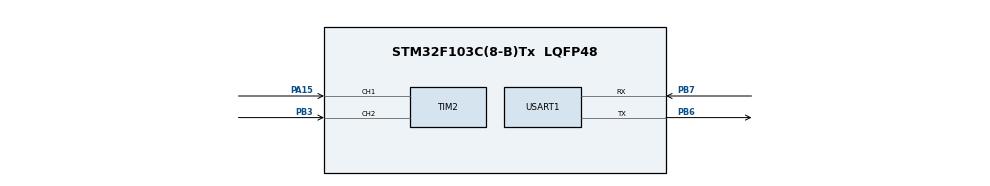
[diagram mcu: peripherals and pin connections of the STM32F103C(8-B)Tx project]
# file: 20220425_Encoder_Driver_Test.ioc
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Mcu.Family=STM32F1
Mcu.Name=STM32F103C(8-B)Tx
Mcu.Package=LQFP48
NVIC.PriorityGroup=NVIC_PRIORITYGROUP_4
NVIC.TIM4_IRQn=true\:0\:0\:false\:false\:true\:true\:true
PA13.Mode=Serial_Wire
PA13.Signal=SYS_JTMS-SWDIO
PA14.Mode=Serial_Wire
PA14.Signal=SYS_JTCK-SWCLK
PA15.GPIO_PuPd=GPIO_PULLUP
PA15.Signal=S_TIM2_CH1_ETR
PB3.GPIO_PuPd=GPIO_PULLUP
PB3.Signal=S_TIM2_CH2
PB6.Mode=Asynchronous
PB6.Signal=USART1_TX
PB7.Mode=Asynchronous
PB7.Signal=USART1_RX
ProjectManager.HeapSize=0x200
ProjectManager.StackSize=0x400
ProjectManager.TargetToolchain=STM32CubeIDE
RCC.APB1Freq_Value=8000000
RCC.APB2Freq_Value=8000000
SH.S_TIM2_CH1_ETR.0=TIM2_CH1,Encoder_Interface
SH.S_TIM2_CH2.0=TIM2_CH2,Encoder_Interface
TIM2.EncoderMode=TIM_ENCODERMODE_TI12
TIM2.IC1Filter=15
TIM2.IC2Filter=15
TIM4.AutoReloadPreload=TIM_AUTORELOAD_PRELOAD_ENABLE
TIM4.Period=200
TIM4.Prescaler=8000
USART1.VirtualMode=VM_ASYNC
VP_TIM4_VS_ClockSourceINT.Mode=Internal
board=custom

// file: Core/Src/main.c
/* USER CODE BEGIN Header */
/**
  ******************************************************************************
  * @file           : main.c
  * @brief          : Main program body
  ******************************************************************************
  * @attention
  *
  * Copyright (c) 2022 STMicroelectronics.
  * All rights reserved.
  *
  * This software is licensed under terms that can be found in the LICENSE file
  * in the root directory of this software component.
  * If no LICENSE file comes with this software, it is provided AS-IS.
  *
  ******************************************************************************
  */
/* USER CODE END Header */
#include "main.h"
#include "tim.h"
#include "usart.h"
#include "gpio.h"

/* USER CODE BEGIN Includes */
#include "rotary.h"
/* USER CODE END Includes */

/* USER CODE BEGIN PV */
uint8_t	MSG[50] = {'/0'};
/* USER CODE END PV */

void SystemClock_Config(void);

int main(void)
{

  /* MCU Configuration--------------------------------------------------------*/

  /* Reset of all peripherals, Initializes the Flash interface and the Systick. */
  HAL_Init();

  /* Configure the system clock */
  SystemClock_Config();

  /* Initialize all configured peripherals */
  MX_GPIO_Init();
  MX_USART1_UART_Init();
  MX_TIM2_Init();
  MX_TIM4_Init();
  /* USER CODE BEGIN 2 */
  HAL_ROTARY_Start(&htim2, &htim4, 8000);
  /* USER CODE END 2 */

  /* Infinite loop */
  while (1)
  {

    /* USER CODE BEGIN 3 */
	  sprintf(MSG,"RPM = %d\tCount = %d\tDir = %d\r\n",hrotary.RPM,hrotary.Pulses,hrotary.Dir);
	  HAL_UART_Transmit(&huart1, MSG, sizeof(MSG), HAL_MAX_DELAY);
	  HAL_Delay(200);
  }
  /* USER CODE END 3 */
}

void SystemClock_Config(void)
{
  RCC_OscInitTypeDef RCC_OscInitStruct = {0};
  RCC_ClkInitTypeDef RCC_ClkInitStruct = {0};

  /** Initializes the RCC Oscillators according to the specified parameters
  * in the RCC_OscInitTypeDef structure.
  */
  RCC_OscInitStruct.OscillatorType = RCC_OSCILLATORTYPE_HSI;
  RCC_OscInitStruct.HSIState = RCC_HSI_ON;
  RCC_OscInitStruct.HSICalibrationValue = RCC_HSICALIBRATION_DEFAULT;
  RCC_OscInitStruct.PLL.PLLState = RCC_PLL_NONE;
  if (HAL_RCC_OscConfig(&RCC_OscInitStruct) != HAL_OK)
  {
    Error_Handler();
  }
  /** Initializes the CPU, AHB and APB buses clocks
  */
  RCC_ClkInitStruct.ClockType = RCC_CLOCKTYPE_HCLK|RCC_CLOCKTYPE_SYSCLK
                              |RCC_CLOCKTYPE_PCLK1|RCC_CLOCKTYPE_PCLK2;
  RCC_ClkInitStruct.SYSCLKSource = RCC_SYSCLKSOURCE_HSI;
  RCC_ClkInitStruct.AHBCLKDivider = RCC_SYSCLK_DIV1;
  RCC_ClkInitStruct.APB1CLKDivider = RCC_HCLK_DIV1;
  RCC_ClkInitStruct.APB2CLKDivider = RCC_HCLK_DIV1;

  if (HAL_RCC_ClockConfig(&RCC_ClkInitStruct, FLASH_LATENCY_0) != HAL_OK)
  {
    Error_Handler();
  }
}

void Error_Handler(void)
{
  __disable_irq();
  while (1)
  {
  }
}
